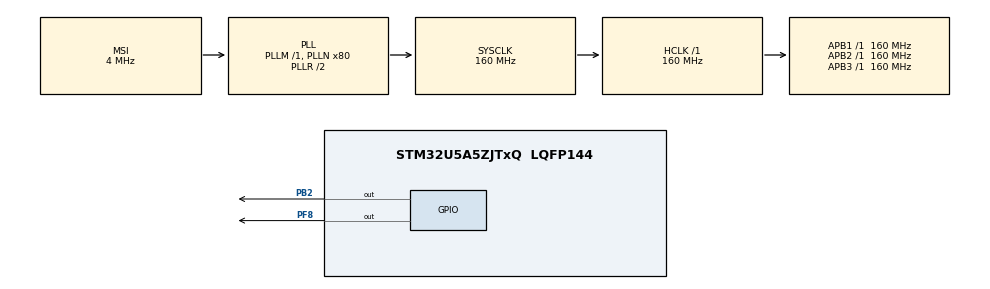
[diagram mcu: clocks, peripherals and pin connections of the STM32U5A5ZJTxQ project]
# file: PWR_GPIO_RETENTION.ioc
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CORTEX_M33_NS.userName=CORTEX_M33
Mcu.Family=STM32U5
Mcu.Name=STM32U5A5ZJTxQ
Mcu.Package=LQFP144
NVIC.PriorityGroup=NVIC_PRIORITYGROUP_4
PB2.PinState=GPIO_PIN_SET
PB2.Signal=GPIO_Output
PF8.Signal=GPIO_Output
PWR.PowerMode=PWR_SMPS_SUPPLY
ProjectManager.HeapSize=0x200
ProjectManager.StackSize=0x400
ProjectManager.TargetToolchain=EWARM V8.32
RCC.ADCFreq_Value=16000000
RCC.AHBFreq_Value=160000000
RCC.APB1Freq_Value=160000000
RCC.APB1TimFreq_Value=160000000
RCC.APB2Freq_Value=160000000
RCC.APB2TimFreq_Value=160000000
RCC.APB3Freq_Value=160000000
RCC.CortexFreq_Value=160000000
RCC.DACCLockSelectionVirtual=RCC_DAC1CLKSOURCE_LSI
RCC.EPOD_VALUE=4000000
RCC.HCLKFreq_Value=160000000
RCC.HSE_VALUE=16000000
RCC.HSI48_VALUE=48000000
RCC.HSI_VALUE=16000000
RCC.LSE_VALUE=32768
RCC.LSIDIV_VALUE=32000
RCC.MSI_VALUE=4000000
RCC.PLLN=80
RCC.SYSCLKFreq_VALUE=160000000
RCC.SYSCLKSource=RCC_SYSCLKSOURCE_PLLCLK
RCC.VCOOutputFreq_Value=320000000
VP_ICACHE_VS_ICACHE.Mode=DirectMappedCache
VP_PWR_VS_DBSignals.Mode=DisableDeadBatterySignals
VP_PWR_VS_LPOM.Mode=PowerOptimisation
VP_PWR_VS_SECSignals.Mode=Security/Privilege
board=custom

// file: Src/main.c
/* USER CODE BEGIN Header */
/**
  ******************************************************************************
  * @file    PWR/PWR_GPIO_RETENTION/Src/main.c
  * @author  MCD Application Team
  * @brief   This example describes how to configure and use GPIOs with power retention
  *          through the HAL API.
  ******************************************************************************
  * @attention
  *
  * Copyright (c) 2025 STMicroelectronics.
  * All rights reserved.
  *
  * This software is licensed under terms that can be found in the LICENSE file
  * in the root directory of this software component.
  * If no LICENSE file comes with this software, it is provided AS-IS.
  *
  ******************************************************************************
  */
/* USER CODE END Header */
#include "main.h"

/* USER CODE BEGIN PD */
#define LED_TOGGLE_DELAY         100U
/* USER CODE END PD */

/* USER CODE BEGIN PV */
volatile uint32_t TimingDelay = LED_TOGGLE_DELAY;
/* USER CODE END PV */

void SystemClock_Config(void);
static void SystemPower_Config(void);
static void MX_GPIO_Init(void);
static void MX_ICACHE_Init(void);

int main(void)
{

  /* USER CODE BEGIN 1 */
  /* STM32U5xx HAL library initialization:
       - Configure the Flash prefetch
       - Configure the Systick to generate an interrupt each 1 msec
       - Set NVIC Group Priority to 4
       - Low Level Initialization
     */
  /* USER CODE END 1 */

  /* MCU Configuration--------------------------------------------------------*/

  /* Reset of all peripherals, Initializes the Flash interface and the Systick. */
  HAL_Init();

  /* Configure the System Power */
  SystemPower_Config();

  /* Configure the system clock */
  SystemClock_Config();

  /* Initialize all configured peripherals */
  MX_GPIO_Init();
  MX_ICACHE_Init();
  /* USER CODE BEGIN 2 */

  /* Configure LED2 */
  BSP_LED_Init(LED2);
  /* Configure LED3 for error handler */
  BSP_LED_Init(LED3);

  /* Check if the system was resumed from Standby mode */
  if (__HAL_PWR_GET_FLAG(PWR_FLAG_SBF) == RESET)
  {
    /* Configure PWR pull-up for GPIOB Pin 2 */
    HAL_PWREx_EnableGPIOPullUp(PWR_GPIO_B, PWR_GPIO_BIT_2);

    /* Configure PWR pull-down for GPIOF Pin 8 */
    HAL_PWREx_EnableGPIOPullDown(PWR_GPIO_F, PWR_GPIO_BIT_8);

    /* Apply the pull-up and pull-down configuration */
    HAL_PWREx_EnablePullUpPullDownConfig();

    /* The Following Wakeup sequence is mandatory to Standby mode entry
    - Clear wake up pin flag depending in edge detection & pin level.
    - Enable wakeup.
    - Enter the Standby mode.
    */
    /* Clear all related wakeup flags*/
    __HAL_PWR_CLEAR_FLAG(PWR_WAKEUP_FLAG2);

    /* Enable WakeUp Pin PWR_WAKEUP_PIN2 connected to PC.13 */
    HAL_PWR_EnableWakeUpPin(PWR_WAKEUP_PIN2_HIGH_1);

    /* Insert 500 ms delay */
    HAL_Delay(500);

    /* -3- Enter the Standby mode */
    HAL_PWR_EnterSTANDBYMode();
  }
  else
  {
    /* Clear Standby flag */
    __HAL_PWR_CLEAR_FLAG(PWR_FLAG_SBF);
    /* Check and Clear the Wakeup flag */
    if (__HAL_PWR_GET_FLAG(PWR_WAKEUP_FLAG2) != RESET)
    {
      /* Clear all related wakeup flags*/
      __HAL_PWR_CLEAR_FLAG(PWR_WAKEUP_FLAG2);
    }

    /* Disable the pull-up and pull-down configuration */
    HAL_PWREx_DisablePullUpPullDownConfig();
    HAL_PWREx_DisableGPIOPullUp(PWR_GPIO_B, PWR_GPIO_BIT_2);
    HAL_PWREx_DisableGPIOPullDown(PWR_GPIO_F, PWR_GPIO_BIT_8);

  }

  /* This code will never be reached! */
  /* USER CODE END 2 */

  /* Infinite loop */
  while (1)
  {

  }
}

void SystemClock_Config(void)
{
  RCC_OscInitTypeDef RCC_OscInitStruct = {0};
  RCC_ClkInitTypeDef RCC_ClkInitStruct = {0};

  /** Configure the main internal regulator output voltage
  */
  if (HAL_PWREx_ControlVoltageScaling(PWR_REGULATOR_VOLTAGE_SCALE1) != HAL_OK)
  {
    Error_Handler();
  }

  /** Initializes the CPU, AHB and APB buses clocks
  */
  RCC_OscInitStruct.OscillatorType = RCC_OSCILLATORTYPE_MSI;
  RCC_OscInitStruct.MSIState = RCC_MSI_ON;
  RCC_OscInitStruct.MSICalibrationValue = RCC_MSICALIBRATION_DEFAULT;
  RCC_OscInitStruct.MSIClockRange = RCC_MSIRANGE_4;
  RCC_OscInitStruct.PLL.PLLState = RCC_PLL_ON;
  RCC_OscInitStruct.PLL.PLLSource = RCC_PLLSOURCE_MSI;
  RCC_OscInitStruct.PLL.PLLMBOOST = RCC_PLLMBOOST_DIV1;
  RCC_OscInitStruct.PLL.PLLM = 1;
  RCC_OscInitStruct.PLL.PLLN = 80;
  RCC_OscInitStruct.PLL.PLLP = 2;
  RCC_OscInitStruct.PLL.PLLQ = 2;
  RCC_OscInitStruct.PLL.PLLR = 2;
  RCC_OscInitStruct.PLL.PLLRGE = RCC_PLLVCIRANGE_0;
  RCC_OscInitStruct.PLL.PLLFRACN = 0;
  if (HAL_RCC_OscConfig(&RCC_OscInitStruct) != HAL_OK)
  {
    Error_Handler();
  }

  /** Initializes the CPU, AHB and APB buses clocks
  */
  RCC_ClkInitStruct.ClockType = RCC_CLOCKTYPE_HCLK|RCC_CLOCKTYPE_SYSCLK
                              |RCC_CLOCKTYPE_PCLK1|RCC_CLOCKTYPE_PCLK2
                              |RCC_CLOCKTYPE_PCLK3;
  RCC_ClkInitStruct.SYSCLKSource = RCC_SYSCLKSOURCE_PLLCLK;
  RCC_ClkInitStruct.AHBCLKDivider = RCC_SYSCLK_DIV1;
  RCC_ClkInitStruct.APB1CLKDivider = RCC_HCLK_DIV1;
  RCC_ClkInitStruct.APB2CLKDivider = RCC_HCLK_DIV1;
  RCC_ClkInitStruct.APB3CLKDivider = RCC_HCLK_DIV1;

  if (HAL_RCC_ClockConfig(&RCC_ClkInitStruct, FLASH_LATENCY_4) != HAL_OK)
  {
    Error_Handler();
  }
}

/**
  * @brief Power Configuration
  * @retval None
  */
static void SystemPower_Config(void)
{

  /*
   * Disable the internal Pull-Up in Dead Battery pins of UCPD peripheral
   */
  HAL_PWREx_DisableUCPDDeadBattery();

  /*
   * Switch to SMPS regulator instead of LDO
   */
  if (HAL_PWREx_ConfigSupply(PWR_SMPS_SUPPLY) != HAL_OK)
  {
    Error_Handler();
  }
}

static void MX_ICACHE_Init(void)
{

  /** Enable instruction cache in 1-way (direct mapped cache)
  */
  if (HAL_ICACHE_ConfigAssociativityMode(ICACHE_1WAY) != HAL_OK)
  {
    Error_Handler();
  }
  if (HAL_ICACHE_Enable() != HAL_OK)
  {
    Error_Handler();
  }

}

static void MX_GPIO_Init(void)
{
  GPIO_InitTypeDef GPIO_InitStruct = {0};

  /* GPIO Ports Clock Enable */
  __HAL_RCC_GPIOF_CLK_ENABLE();
  __HAL_RCC_GPIOB_CLK_ENABLE();

  /*Configure GPIO pin Output Level */
  HAL_GPIO_WritePin(GPIOF, GPIO_PIN_8, GPIO_PIN_RESET);

  /*Configure GPIO pin Output Level */
  HAL_GPIO_WritePin(GPIOB, GPIO_PIN_2, GPIO_PIN_SET);

  /*Configure GPIO pin : PF8 */
  GPIO_InitStruct.Pin = GPIO_PIN_8;
  GPIO_InitStruct.Mode = GPIO_MODE_OUTPUT_PP;
  GPIO_InitStruct.Pull = GPIO_NOPULL;
  GPIO_InitStruct.Speed = GPIO_SPEED_FREQ_LOW;
  HAL_GPIO_Init(GPIOF, &GPIO_InitStruct);

  /*Configure GPIO pin : PB2 */
  GPIO_InitStruct.Pin = GPIO_PIN_2;
  GPIO_InitStruct.Mode = GPIO_MODE_OUTPUT_PP;
  GPIO_InitStruct.Pull = GPIO_NOPULL;
  GPIO_InitStruct.Speed = GPIO_SPEED_FREQ_LOW;
  HAL_GPIO_Init(GPIOB, &GPIO_InitStruct);

}

/* USER CODE BEGIN 4 */
void HAL_SYSTICK_Callback(void)
{
  if (TimingDelay != 0)
  {
    TimingDelay--;
  }
  else
  {
    /* Toggle LED2 */
    BSP_LED_Toggle(LED2);
    TimingDelay = LED_TOGGLE_DELAY;
  }
}
/* USER CODE END 4 */

void Error_Handler(void)
{
  /* USER CODE BEGIN Error_Handler_Debug */
  /* User can add his own implementation to report the HAL error return state */

  /* Turn LED3 on */
  BSP_LED_On(LED3);
  while (1)
  {
  }

  /* USER CODE END Error_Handler_Debug */
}
